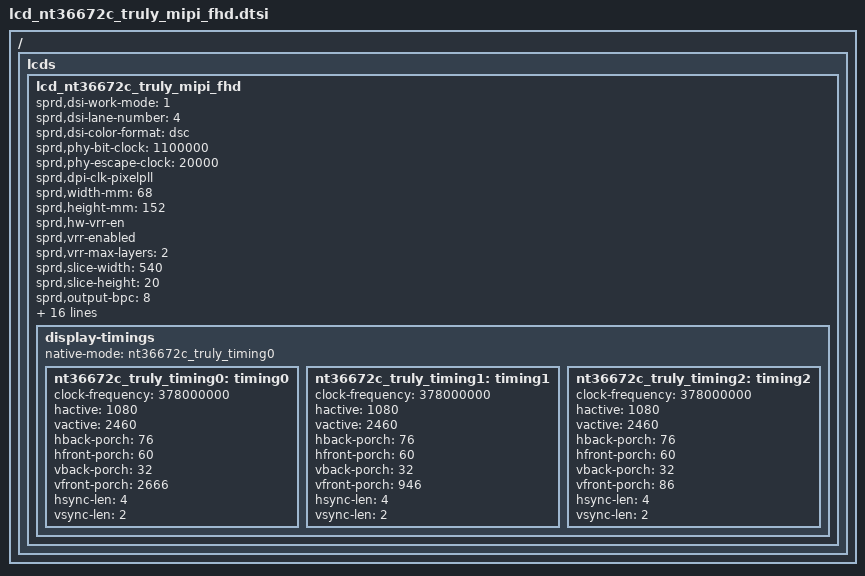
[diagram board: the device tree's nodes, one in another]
// SPDX-License-Identifier: GPL-2.0-only
/*
 * NT36672c truly lcd config dtsi file for spreadtrum
 *
 * Copyright (C) 2021, Spreadtrum Communications Inc.
 */
/ {
	fragment {
		target-path = "/";
		__overlay__ {
			lcds {
				lcd_nt36672c_truly_mipi_fhd: lcd_nt36672c_truly_mipi_fhd {

					sprd,dsi-work-mode = <1>; /* video burst mode*/
					sprd,dsi-lane-number = <4>;
					sprd,dsi-color-format = "dsc";

					sprd,phy-bit-clock = <1100000>;  /* kbps */
					sprd,phy-escape-clock = <20000>;/* kHz */
					sprd,dpi-clk-pixelpll;

					sprd,width-mm = <68>;
					sprd,height-mm = <152>;

					sprd,hw-vrr-en;
					sprd,vrr-enabled;
					sprd,vrr-max-layers = <2>;

					sprd,slice-width = <540>;
					sprd,slice-height = <20>;
					sprd,output-bpc = <8>;
					sprd,dsc-enable = <1>;
					sprd,dual-dsi-enable = <0>;

					sprd,esd-check-enable = <0>;
					sprd,esd-check-mode = <0>;  // 0:Reg mode 1:TE mode
					sprd,esd-check-period = <1000>;
					sprd,esd-check-register = <0x0A>;
					sprd,esd-check-value = <0x9C>;

					sprd,reset-on-sequence = <1 15>, <0 15>, <1 15>;
					sprd,reset-off-sequence = <0 5>;

					sprd,use-gen-write;

					sprd,initial-command = [
						15 00 00 02 FF 10
						15 00 00 02 FB 01
						15 00 00 02 B0 00
						39 00 00 02 C0 03
						39 00 00 11 C1 89 28 00 14 02 00 02 0E 01 E8 00 07 05 0E 05 16
						39 00 00 03 C2 10 F0
						15 00 00 02 E9 01

						15 00 00 02 FF 20
						15 00 00 02 FB 01
						15 00 00 02 01 66
						15 00 00 02 07 32
						15 00 00 02 1B 01
						15 00 00 02 1F 02
						15 00 00 02 20 03
						15 00 00 02 5C 90
						15 00 00 02 5E E6
						15 00 00 02 69 D0
						15 00 00 02 89 18
						15 00 00 02 8A 18
						15 00 00 02 95 D1
						15 00 00 02 96 D1
						15 00 00 02 F2 65
						15 00 00 02 F4 65
						15 00 00 02 F6 65
						15 00 00 02 F8 65

						15 00 00 02 23 08
						15 00 00 02 24 01
						15 00 00 02 25 65
						15 00 00 02 26 92

						15 00 00 02 FF 21
						15 00 00 02 FB 01

						15 00 00 02 FF 23
						15 00 00 02 FB 01
						15 00 00 02 07 20
						15 00 00 02 08 0A
						15 00 00 02 09 0E

						15 00 00 02 FF 24
						15 00 00 02 FB 01
						15 00 00 02 00 26
						15 00 00 02 01 13
						15 00 00 02 02 27
						15 00 00 02 03 15
						15 00 00 02 04 28
						15 00 00 02 05 17
						15 00 00 02 07 24
						15 00 00 02 08 24
						15 00 00 02 0A 22
						15 00 00 02 0C 10
						15 00 00 02 0D 0F
						15 00 00 02 0E 01
						15 00 00 02 10 2D
						15 00 00 02 11 2F
						15 00 00 02 12 31
						15 00 00 02 13 33
						15 00 00 02 15 0B
						15 00 00 02 17 0C
						15 00 00 02 18 26
						15 00 00 02 19 13
						15 00 00 02 1A 27
						15 00 00 02 1B 15
						15 00 00 02 1C 28
						15 00 00 02 1D 17
						15 00 00 02 1F 24
						15 00 00 02 20 24
						15 00 00 02 22 22
						15 00 00 02 24 10
						15 00 00 02 25 0F
						15 00 00 02 26 01
						15 00 00 02 28 2C
						15 00 00 02 29 2E
						15 00 00 02 2A 30
						15 00 00 02 2B 32
						15 00 00 02 2F 0B
						15 00 00 02 31 0C
						15 00 00 02 32 09
						15 00 00 02 33 03
						15 00 00 02 34 03
						15 00 00 02 36 33
						15 00 00 02 4E 30
						15 00 00 02 4F 30
						15 00 00 02 53 30
						15 00 00 02 77 80
						15 00 00 02 79 22
						15 00 00 02 7A 03
						15 00 00 02 7B 8D
						15 00 00 02 7D 03
						15 00 00 02 80 03
						15 00 00 02 81 03
						15 00 00 02 82 13
						15 00 00 02 84 31
						15 00 00 02 85 13
						15 00 00 02 86 22
						15 00 00 02 87 31
						15 00 00 02 90 13
						15 00 00 02 92 31
						15 00 00 02 93 13
						15 00 00 02 94 22
						15 00 00 02 95 31
						15 00 00 02 9C F4
						15 00 00 02 9D 01
						15 00 00 02 A0 0D
						15 00 00 02 A2 0D
						15 00 00 02 A3 03
						15 00 00 02 A4 03
						15 00 00 02 A5 03
						15 00 00 02 C4 80
						15 00 00 02 C6 C0
						15 00 00 02 C9 00
						15 00 00 02 CC 80
						15 00 00 02 D9 80
						15 00 00 02 E9 03

						15 00 00 02 FF 25
						15 00 00 02 FB 01
						15 00 00 02 0F 1B
						15 00 00 02 18 20
						15 00 00 02 19 E4
						15 00 00 02 21 40
						15 00 00 02 63 8F
						15 00 00 02 66 5D
						15 00 00 02 67 16
						15 00 00 02 68 58
						15 00 00 02 69 10
						15 00 00 02 6B 00
						15 00 00 02 70 E5
						15 00 00 02 71 6D
						15 00 00 02 77 62
						15 00 00 02 7E 2D
						15 00 00 02 84 78
						15 00 00 02 85 75
						15 00 00 02 8D 00
						15 00 00 02 C1 A9
						15 00 00 02 C2 5A
						15 00 00 02 C3 07
						15 00 00 02 C4 11
						15 00 00 02 C6 11
						15 00 00 02 F0 05
						15 00 00 02 F1 14

						15 00 00 02 FF 26
						15 00 00 02 FB 01
						15 00 00 02 00 10
						15 00 00 02 01 F0
						15 00 00 02 03 00
						15 00 00 02 04 F0
						15 00 00 02 05 08
						15 00 00 02 06 10
						15 00 00 02 08 10
						15 00 00 02 14 06
						15 00 00 02 15 01
						15 00 00 02 74 AF
						15 00 00 02 81 0D
						15 00 00 02 83 03
						15 00 00 02 84 02
						15 00 00 02 85 01
						15 00 00 02 86 02
						15 00 00 02 87 01
						15 00 00 02 88 04
						15 00 00 02 8A 1A
						15 00 00 02 8B 11
						15 00 00 02 8C 24
						15 00 00 02 8E 42
						15 00 00 02 8F 11
						15 00 00 02 90 11
						15 00 00 02 91 11
						15 00 00 02 99 21
						15 00 00 02 9A 80
						15 00 00 02 9B 04
						15 00 00 02 9C 00
						15 00 00 02 9D 00
						15 00 00 02 9E 00

						15 00 00 02 FF 27
						15 00 00 02 FB 01
						15 00 00 02 01 9C
						15 00 00 02 20 81
						15 00 00 02 21 67
						15 00 00 02 25 81
						15 00 00 02 26 A1
						15 00 00 02 6E 12
						15 00 00 02 6F 00
						15 00 00 02 70 00
						15 00 00 02 71 00
						15 00 00 02 72 00
						15 00 00 02 73 76
						15 00 00 02 74 10
						15 00 00 02 75 32
						15 00 00 02 76 54
						15 00 00 02 77 00
						15 00 00 02 7D 09
						15 00 00 02 7E 9F
						15 00 00 02 80 27
						15 00 00 02 82 09
						15 00 00 02 83 9F
						15 00 00 02 88 03
						15 00 00 02 89 03
						15 00 00 02 E3 01
						15 00 00 02 E4 DF
						15 00 00 02 E9 02
						15 00 00 02 EA 2C

						15 00 00 02 FF 2A
						15 00 00 02 FB 01
						15 00 00 02 00 91
						15 00 00 02 03 20
						15 00 00 02 07 64
						15 00 00 02 0A 60
						15 00 00 02 0D 40
						15 00 00 02 0E 02
						15 00 00 02 11 F6
						15 00 00 02 15 0F
						15 00 00 02 16 07
						15 00 00 02 19 0E
						15 00 00 02 1A DB
						15 00 00 02 1B 14
						15 00 00 02 1D 36
						15 00 00 02 1E 36
						15 00 00 02 1F 3E
						15 00 00 02 20 36
						15 00 00 02 28 EE
						15 00 00 02 29 0D
						15 00 00 02 2A 10
						15 00 00 02 2D 06
						15 00 00 02 2F 02
						15 00 00 02 30 4A
						15 00 00 02 31 99
						15 00 00 02 33 63
						15 00 00 02 34 F0
						15 00 00 02 35 46
						15 00 00 02 36 0B
						15 00 00 02 37 E9
						15 00 00 02 38 4C
						15 00 00 02 39 05
						15 00 00 02 3A 4A
						15 00 00 02 46 40
						15 00 00 02 47 02
						15 00 00 02 4A F6
						15 00 00 02 4E 0F
						15 00 00 02 4F 07
						15 00 00 02 52 0E
						15 00 00 02 54 14
						15 00 00 02 56 36
						15 00 00 02 57 4D
						15 00 00 02 58 61
						15 00 00 02 59 4D
						15 00 00 02 60 80
						15 00 00 02 61 F9
						15 00 00 02 62 06
						15 00 00 02 63 2A
						15 00 00 02 66 01
						15 00 00 02 67 45
						15 00 00 02 68 BD
						15 00 00 02 6B FB
						15 00 00 02 6C 32
						15 00 00 02 6D 0A
						15 00 00 02 6E F6
						15 00 00 02 70 06
						15 00 00 02 71 45

						15 00 00 02 FF 2C
						15 00 00 02 FB 01
						15 00 00 02 00 03
						15 00 00 02 01 03
						15 00 00 02 02 03
						15 00 00 02 03 14
						15 00 00 02 04 14
						15 00 00 02 05 14
						15 00 00 02 0E 4B
						15 00 00 02 17 47
						15 00 00 02 18 47
						15 00 00 02 19 47
						15 00 00 02 2D AF
						15 00 00 02 2F 10
						15 00 00 02 30 F0
						15 00 00 02 32 00
						15 00 00 02 33 F0
						15 00 00 02 35 19
						15 00 00 02 37 19
						15 00 00 02 4D 14
						15 00 00 02 4E 03
						15 00 00 02 4F 06

						15 00 00 02 FF E0
						15 00 00 02 FB 01
						15 00 00 02 35 82

						15 00 00 02 FF F0
						15 00 00 02 FB 01
						15 00 00 02 1C 01
						15 00 00 02 33 01
						15 00 00 02 5A 00
						15 00 00 02 D2 50

						15 00 00 02 FF D0
						15 00 00 02 FB 01
						15 00 00 02 53 22
						15 00 00 02 54 02

						15 00 00 02 FF C0
						15 00 00 02 FB 01
						15 00 00 02 9C 11
						15 00 00 02 9D 11

						15 00 00 02 FF 2B
						15 00 00 02 FB 01
						15 00 00 02 B7 19
						15 00 00 02 B8 18
						15 00 00 02 C0 08

						15 00 00 02 FF 20
						15 00 00 02 FB 01
						39 00 00 11 B0 00 00 00 2C 00 5E 00 83 00 A1 00 BA 00 D0 00 E3
						39 00 00 11 B1 00 F5 01 2F 01 57 01 99 01 C5 02 0E 02 42 02 45
						39 00 00 11 B2 02 79 02 B3 02 DA 03 0B 03 2C 03 54 03 63 03 73
						39 00 00 0F B3 03 87 03 9F 03 B8 03 CB 03 D6 03 D8 00 00
						39 00 00 11 B4 00 00 00 2C 00 5E 00 83 00 A1 00 BA 00 D0 00 E3
						39 00 00 11 B5 00 F5 01 2F 01 57 01 99 01 C5 02 0E 02 42 02 45
						39 00 00 11 B6 02 79 02 B3 02 DA 03 0B 03 2C 03 54 03 63 03 73
						39 00 00 0F B7 03 87 03 9F 03 B8 03 CB 03 D6 03 D8 00 00
						39 00 00 11 B8 00 00 00 2C 00 5E 00 83 00 A1 00 BA 00 D0 00 E3
						39 00 00 11 B9 00 F5 01 2F 01 57 01 99 01 C5 02 0E 02 42 02 45
						39 00 00 11 BA 02 79 02 B3 02 DA 03 0B 03 2C 03 54 03 63 03 73
						39 00 00 0F BB 03 87 03 9F 03 B8 03 CB 03 D6 03 D8 00 00

						15 00 00 02 FF 21
						15 00 00 02 FB 01

						39 00 00 11 B0 00 00 00 2C 00 5E 00 83 00 A1 00 BA 00 D0 00 E3
						39 00 00 11 B1 00 F5 01 2F 01 57 01 99 01 C5 02 0E 02 42 02 45
						39 00 00 11 B2 02 79 02 B3 02 DA 03 0B 03 2C 03 54 03 63 03 73
						39 00 00 0F B3 03 87 03 9F 03 B8 03 CB 03 D6 03 D8 00 00
						39 00 00 11 B4 00 00 00 2C 00 5E 00 83 00 A1 00 BA 00 D0 00 E3
						39 00 00 11 B5 00 F5 01 2F 01 57 01 99 01 C5 02 0E 02 42 02 45
						39 00 00 11 B6 02 79 02 B3 02 DA 03 0B 03 2C 03 54 03 63 03 73
						39 00 00 0F B7 03 87 03 9F 03 B8 03 CB 03 D6 03 D8 00 00
						39 00 00 11 B8 00 00 00 2C 00 5E 00 83 00 A1 00 BA 00 D0 00 E3
						39 00 00 11 B9 00 F5 01 2F 01 57 01 99 01 C5 02 0E 02 42 02 45
						39 00 00 11 BA 02 79 02 B3 02 DA 03 0B 03 2C 03 54 03 63 03 73
						39 00 00 0F BB 03 87 03 9F 03 B8 03 CB 03 D6 03 D8 00 00

						15 00 00 02 FF 10
						05 C8 00 01 11
						05 32 00 01 29
						];

					sprd,sleep-in-command = [
						13 0A 00 01 28
						13 78 00 01 10
						23 0a 00 02 4f 01
						];
					sprd,sleep-out-command = [
						13 78 00 01 11
						13 32 00 01 29
						];

					display-timings {
						native-mode = <&nt36672c_truly_timing0>;

						nt36672c_truly_timing0: timing0 {
							clock-frequency = <378000000>;
							hactive = <1080>;
							vactive = <2460>;
							hback-porch = <76>;
							hfront-porch = <60>;
							vback-porch = <32>;
							vfront-porch = <2666>;
							hsync-len = <4>;
							vsync-len = <2>;
						};

						nt36672c_truly_timing1: timing1 {
							clock-frequency = <378000000>;
							hactive = <1080>;
							vactive = <2460>;
							hback-porch = <76>;
							hfront-porch = <60>;
							vback-porch = <32>;
							vfront-porch = <946>;
							hsync-len = <4>;
							vsync-len = <2>;
						};

						nt36672c_truly_timing2: timing2 {
							clock-frequency = <378000000>;
							hactive = <1080>;
							vactive = <2460>;
							hback-porch = <76>;
							hfront-porch = <60>;
							vback-porch = <32>;
							vfront-porch = <86>;
							hsync-len = <4>;
							vsync-len = <2>;
						};
					};
				};
			};
		};
	};
};
